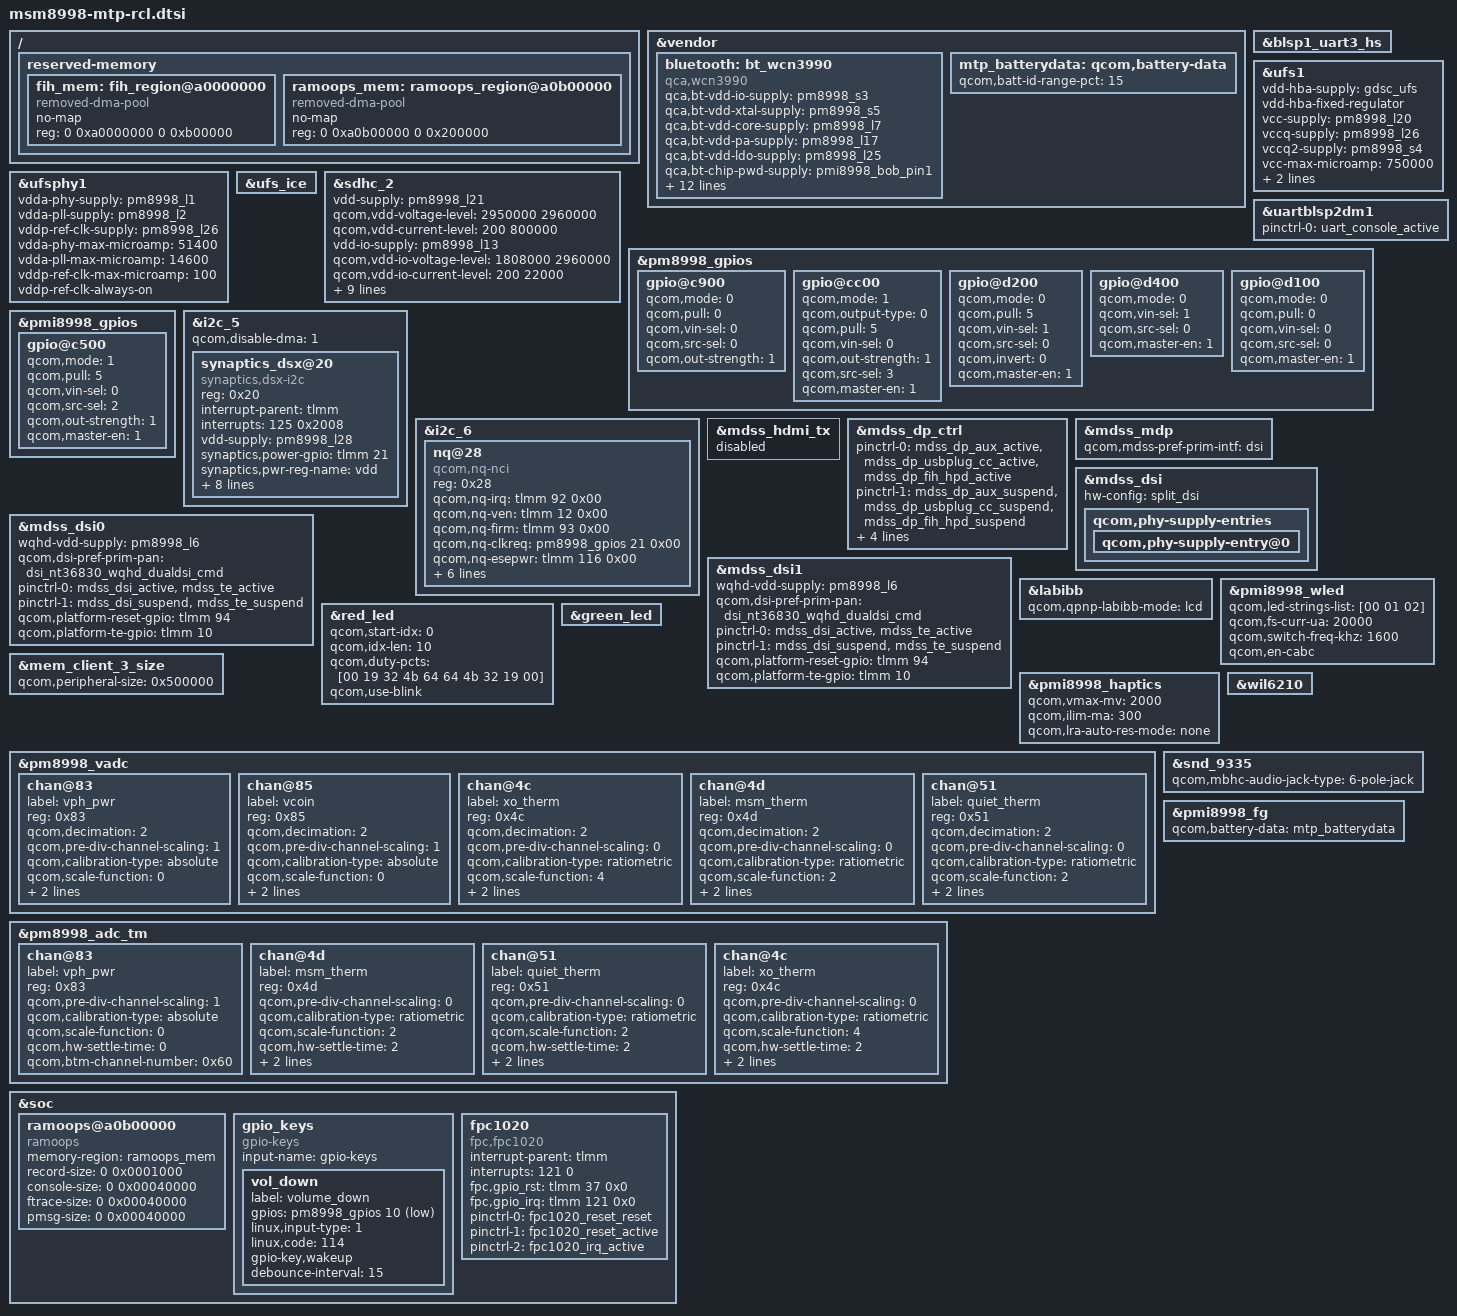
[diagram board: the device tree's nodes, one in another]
/* Copyright (c) 2016-2018, The Linux Foundation. All rights reserved.
 *
 * This program is free software; you can redistribute it and/or modify
 * it under the terms of the GNU General Public License version 2 and
 * only version 2 as published by the Free Software Foundation.
 *
 * This program is distributed in the hope that it will be useful,
 * but WITHOUT ANY WARRANTY; without even the implied warranty of
 * MERCHANTABILITY or FITNESS FOR A PARTICULAR PURPOSE.  See the
 * GNU General Public License for more details.
 */

#include <dt-bindings/interrupt-controller/irq.h>
#include "msm-pm8998-rcl.dtsi"
#include "msm-pmi8998-rcl.dtsi"
#include "msm8998-camera-sensor-mtp-rcl.dtsi"
#include "msm8998-pinctrl-rcl.dtsi"
#include "msm8998-regulator-rcl.dtsi"

/ {
	reserved-memory {
		fih_mem: fih_region@a0000000 { /* for FIH feature */
			compatible = "removed-dma-pool";
			no-map;
			reg = <0 0xa0000000 0 0xb00000>;
		};

		ramoops_mem: ramoops_region@a0b00000 { /* for ramoops feature */
			compatible = "removed-dma-pool";
			no-map;
			reg = <0 0xa0b00000 0 0x200000>;
		};
	};
};

&vendor {
	bluetooth: bt_wcn3990 {
		compatible = "qca,wcn3990";
		qca,bt-vdd-io-supply = <&pm8998_s3>;
		qca,bt-vdd-xtal-supply = <&pm8998_s5>;
		qca,bt-vdd-core-supply = <&pm8998_l7>;
		qca,bt-vdd-pa-supply = <&pm8998_l17>;
		qca,bt-vdd-ldo-supply = <&pm8998_l25>;
		qca,bt-chip-pwd-supply = <&pmi8998_bob_pin1>;
		clocks = <&clock_gcc clk_rf_clk2_pin>;
		clock-names = "rf_clk2";

		qca,bt-vdd-io-voltage-level = <1352000 1352000>;
		qca,bt-vdd-xtal-voltage-level = <2040000 2040000>;
		qca,bt-vdd-core-voltage-level = <1800000 1800000>;
		qca,bt-vdd-pa-voltage-level = <1304000 1304000>;
		qca,bt-vdd-ldo-voltage-level = <3312000 3312000>;
		qca,bt-chip-pwd-voltage-level = <3600000 3600000>;

		qca,bt-vdd-io-current-level = <1>; /* LPM/PFM */
		qca,bt-vdd-xtal-current-level = <1>; /* LPM/PFM */
		qca,bt-vdd-core-current-level = <1>; /* LPM/PFM */
		qca,bt-vdd-pa-current-level = <1>; /* LPM/PFM */
		qca,bt-vdd-ldo-current-level = <1>; /* LPM/PFM */
	};
};

&blsp1_uart3_hs {
	status = "ok";
};

&ufsphy1 {
	vdda-phy-supply = <&pm8998_l1>;
	vdda-pll-supply = <&pm8998_l2>;
	vddp-ref-clk-supply = <&pm8998_l26>;
	vdda-phy-max-microamp = <51400>;
	vdda-pll-max-microamp = <14600>;
	vddp-ref-clk-max-microamp = <100>;
	vddp-ref-clk-always-on;
	status = "ok";
};

&ufs1 {
	vdd-hba-supply = <&gdsc_ufs>;
	vdd-hba-fixed-regulator;
	vcc-supply = <&pm8998_l20>;
	vccq-supply = <&pm8998_l26>;
	vccq2-supply = <&pm8998_s4>;
	vcc-max-microamp = <750000>;
	vccq-max-microamp = <560000>;
	vccq2-max-microamp = <750000>;
	status = "ok";
};

&ufs_ice {
	status = "ok";
};

&sdhc_2 {
	vdd-supply = <&pm8998_l21>;
	qcom,vdd-voltage-level = <2950000 2960000>;
	qcom,vdd-current-level = <200 800000>;

	vdd-io-supply = <&pm8998_l13>;
	qcom,vdd-io-voltage-level = <1808000 2960000>;
	qcom,vdd-io-current-level = <200 22000>;

	pinctrl-names = "active", "sleep";
	pinctrl-0 = <&sdc2_clk_on  &sdc2_cmd_on &sdc2_data_on &sdc2_cd_on>;
	pinctrl-1 = <&sdc2_clk_off &sdc2_cmd_off &sdc2_data_off &sdc2_cd_off>;

	qcom,clk-rates = <400000 20000000 25000000
				50000000 100000000 200000000>;
	qcom,bus-speed-mode = "SDR12", "SDR25", "SDR50", "DDR50", "SDR104";

	cd-gpios = <&tlmm 95 0x1>;

	status = "ok";
};

&uartblsp2dm1 {
	status = "ok";
	pinctrl-names = "default";
	pinctrl-0 = <&uart_console_active>;
};

&pm8998_gpios {
	/* GPIO 10 for Vol- Key */
	gpio@c900 {
		status = "okay";
		qcom,mode = <0>;
		qcom,pull = <0>;
		qcom,vin-sel = <0>;
		qcom,src-sel = <0>;
		qcom,out-strength = <1>;
	};

	gpio@cc00 { /* GPIO 13 */
		qcom,mode = <1>;
		qcom,output-type = <0>;
		qcom,pull = <5>;
		qcom,vin-sel = <0>;
		qcom,out-strength = <1>;
		qcom,src-sel = <3>;
		qcom,master-en = <1>;
		status = "okay";
	};

	gpio@d200 { /* GPIO 19 - wil6210 refclk3_en */
		qcom,mode = <0>;		/* Input */
		qcom,pull = <5>;		/* No Pull */
		qcom,vin-sel = <1>;		/* VIN1 GPIO_MV */
		qcom,src-sel = <0>;		/* GPIO */
		qcom,invert = <0>;		/* Invert */
		qcom,master-en = <1>;		/* Enable GPIO */
		status = "okay";
	};

	/* GPIO 21 (NFC_CLK_REQ) */
	gpio@d400 {
		qcom,mode = <0>;
		qcom,vin-sel = <1>;
		qcom,src-sel = <0>;
		qcom,master-en = <1>;
		status = "okay";
	};

	/* GPIO 18 SMB138X */
	gpio@d100 {
		qcom,mode = <0>;
		qcom,pull = <0>;
		qcom,vin-sel = <0>;
		qcom,src-sel = <0>;
		qcom,master-en = <1>;
		status = "okay";
	};
};

&pmi8998_gpios {
	/* GPIO 6 for the internal QNOVO discharge FET control signal */
	gpio@c500 {
		status = "okay";
		qcom,mode = <1>;
		qcom,pull = <5>;
		qcom,vin-sel = <0>;
		qcom,src-sel = <2>;
		qcom,out-strength = <1>;
		qcom,master-en = <1>;
	};
};

&i2c_5 {
	status = "okay";
	qcom,disable-dma = <1>;

	synaptics_dsx@20 {
		compatible = "synaptics,dsx-i2c";
		reg = <0x20>;
		interrupt-parent = <&tlmm>;
		interrupts = <125 0x2008>;
		vdd-supply = <&pm8998_l28>;
		synaptics,power-gpio = <&tlmm 21 0x00>;
		synaptics,pwr-reg-name = "vdd";
		synaptics,power-on-state = <1>;
		synaptics,display-coords = <0 0 1599 2559>;
		synaptics,panel-coords = <0 0 1599 2703>;
		synaptics,irq-gpio = <&tlmm 125 0x2008>; /* IRQF_ONESHOT | IRQF_TRIGGER_LOW */
		synaptics,reset-gpio = <&tlmm 89 0x00>;
		synaptics,reset-delay-ms = <100>;
		synaptics,reset-on-state = <0>;
		synaptics,reset-active-ms = <20>;
	};
};

&i2c_6 { /* BLSP1 QUP6 (NFC) */
	status = "okay";
	nq@28 {
		compatible = "qcom,nq-nci";
		reg = <0x28>;
		qcom,nq-irq = <&tlmm 92 0x00>;
		qcom,nq-ven = <&tlmm 12 0x00>;
		qcom,nq-firm = <&tlmm 93 0x00>;
		qcom,nq-clkreq = <&pm8998_gpios 21 0x00>;
		qcom,nq-esepwr = <&tlmm 116 0x00>;
		interrupt-parent = <&tlmm>;
		qcom,clk-src = "BBCLK3";
		interrupts = <92 0>;
		interrupt-names = "nfc_irq";
		pinctrl-names = "nfc_active", "nfc_suspend";
		pinctrl-0 = <&nfc_int_active &nfc_enable_active>;
		pinctrl-1 = <&nfc_int_suspend &nfc_enable_suspend>;
		clocks = <&clock_gcc clk_ln_bb_clk3_pin>;
		clock-names = "ref_clk";
	};
};

&mdss_hdmi_tx {
	status = "disabled";
};

&mdss_dp_ctrl {
	pinctrl-names = "mdss_dp_active", "mdss_dp_sleep";
	pinctrl-0 = <&mdss_dp_aux_active &mdss_dp_usbplug_cc_active &mdss_dp_fih_hpd_active>;
	pinctrl-1 = <&mdss_dp_aux_suspend &mdss_dp_usbplug_cc_suspend &mdss_dp_fih_hpd_suspend>;
	qcom,aux-en-gpio = <&tlmm 77 0>;
	qcom,aux-sel-gpio = <&tlmm 78 0>;
	qcom,hpd-gpio = <&tlmm 115 0>;
	qcom,usbplug-cc-gpio = <&tlmm 38 0>;
};

&mdss_mdp {
	qcom,mdss-pref-prim-intf = "dsi";
};

&mdss_dsi {
	hw-config = "split_dsi";

	qcom,phy-supply-entries {
		qcom,phy-supply-entry@0 {
			/delete-property/ qcom,supply-lp-mode-disable-allowed;
		};
	};
};

&mdss_dsi0 {
	wqhd-vdd-supply = <&pm8998_l6>;

	qcom,dsi-pref-prim-pan = <&dsi_nt36830_wqhd_dualdsi_cmd>;
	pinctrl-names = "mdss_default", "mdss_sleep";
	pinctrl-0 = <&mdss_dsi_active &mdss_te_active>;
	pinctrl-1 = <&mdss_dsi_suspend &mdss_te_suspend>;
	qcom,platform-reset-gpio = <&tlmm 94 0>;
	qcom,platform-te-gpio = <&tlmm 10 0>;
};

&mdss_dsi1 {
	wqhd-vdd-supply = <&pm8998_l6>;

	qcom,dsi-pref-prim-pan = <&dsi_nt36830_wqhd_dualdsi_cmd>;
	pinctrl-names = "mdss_default", "mdss_sleep";
	pinctrl-0 = <&mdss_dsi_active &mdss_te_active>;
	pinctrl-1 = <&mdss_dsi_suspend &mdss_te_suspend>;
	qcom,platform-reset-gpio = <&tlmm 94 0>;
	qcom,platform-te-gpio = <&tlmm 10 0>;
};

&labibb {
	status = "ok";
	qcom,qpnp-labibb-mode = "lcd";
};

&pmi8998_wled {
	qcom,led-strings-list = [00 01 02];
	qcom,fs-curr-ua = <20000>;
	qcom,switch-freq-khz = <1600>;
	qcom,en-cabc;
};

&red_led {
	/delete-property/ linux,default-trigger;
	qcom,start-idx = <0>;
	qcom,idx-len = <10>;
	qcom,duty-pcts = [00 19 32 4b 64
			64 4b 32 19 00];
	qcom,use-blink;
};

&green_led {
	/delete-property/ linux,default-trigger;
};

&mem_client_3_size {
	qcom,peripheral-size = <0x500000>;
};

&pmi8998_haptics {
	status = "okay";
	qcom,vmax-mv = <2000>;
	qcom,ilim-ma = <300>;
	qcom,lra-auto-res-mode = "none";
	/delete-property/ qcom,lra-high-z;
	/delete-property/ qcom,lra-res-cal-period;
};

&pm8998_vadc {
	chan@83 {
		label = "vph_pwr";
		reg = <0x83>;
		qcom,decimation = <2>;
		qcom,pre-div-channel-scaling = <1>;
		qcom,calibration-type = "absolute";
		qcom,scale-function = <0>;
		qcom,hw-settle-time = <0>;
		qcom,fast-avg-setup = <0>;
	};

	chan@85 {
		label = "vcoin";
		reg = <0x85>;
		qcom,decimation = <2>;
		qcom,pre-div-channel-scaling = <1>;
		qcom,calibration-type = "absolute";
		qcom,scale-function = <0>;
		qcom,hw-settle-time = <0>;
		qcom,fast-avg-setup = <0>;
	};

	chan@4c {
		label = "xo_therm";
		reg = <0x4c>;
		qcom,decimation = <2>;
		qcom,pre-div-channel-scaling = <0>;
		qcom,calibration-type = "ratiometric";
		qcom,scale-function = <4>;
		qcom,hw-settle-time = <2>;
		qcom,fast-avg-setup = <0>;
	};

	chan@4d {
		label = "msm_therm";
		reg = <0x4d>;
		qcom,decimation = <2>;
		qcom,pre-div-channel-scaling = <0>;
		qcom,calibration-type = "ratiometric";
		qcom,scale-function = <2>;
		qcom,hw-settle-time = <2>;
		qcom,fast-avg-setup = <0>;
	};

	chan@51 {
		label = "quiet_therm";
		reg = <0x51>;
		qcom,decimation = <2>;
		qcom,pre-div-channel-scaling = <0>;
		qcom,calibration-type = "ratiometric";
		qcom,scale-function = <2>;
		qcom,hw-settle-time = <2>;
		qcom,fast-avg-setup = <0>;
	};
};

&pm8998_adc_tm {
	chan@83 {
		label = "vph_pwr";
		reg = <0x83>;
		qcom,pre-div-channel-scaling = <1>;
		qcom,calibration-type = "absolute";
		qcom,scale-function = <0>;
		qcom,hw-settle-time = <0>;
		qcom,btm-channel-number = <0x60>;
	};

	chan@4d {
		label = "msm_therm";
		reg = <0x4d>;
		qcom,pre-div-channel-scaling = <0>;
		qcom,calibration-type = "ratiometric";
		qcom,scale-function = <2>;
		qcom,hw-settle-time = <2>;
		qcom,btm-channel-number = <0x68>;
		qcom,thermal-node;
	};

	chan@51 {
		label = "quiet_therm";
		reg = <0x51>;
		qcom,pre-div-channel-scaling = <0>;
		qcom,calibration-type = "ratiometric";
		qcom,scale-function = <2>;
		qcom,hw-settle-time = <2>;
		qcom,btm-channel-number = <0x70>;
		qcom,thermal-node;
	};

	chan@4c {
		label = "xo_therm";
		reg = <0x4c>;
		qcom,pre-div-channel-scaling = <0>;
		qcom,calibration-type = "ratiometric";
		qcom,scale-function = <4>;
		qcom,hw-settle-time = <2>;
		qcom,btm-channel-number = <0x78>;
		qcom,thermal-node;
	};
};

&wil6210 {
	status = "ok";
};

&snd_9335 {
	qcom,mbhc-audio-jack-type = "6-pole-jack";
};

&soc {
	ramoops@a0b00000 {
		compatible = "ramoops";
		memory-region = <&ramoops_mem>;
		record-size = <0 0x0001000>;
		console-size = <0 0x00040000>;
		ftrace-size = <0 0x00040000>;
		pmsg-size = <0 0x00040000>;
	};

	gpio_keys {
		compatible = "gpio-keys";
		input-name = "gpio-keys";
		status = "okay";

		vol_down {
			label = "volume_down";
			gpios = <&pm8998_gpios 10 0x1>;
			linux,input-type = <1>;
			linux,code = <114>;
			gpio-key,wakeup;
			debounce-interval = <15>;
		};
	};

	fpc1020 {
		compatible = "fpc,fpc1020";
		status = "ok";
		interrupt-parent = <&tlmm>;
		interrupts = <121 0>;
		fpc,gpio_rst = <&tlmm 37 0x0>;
		fpc,gpio_irq = <&tlmm 121 0x0>;

		pinctrl-names = "fpc1020_reset_reset",
				"fpc1020_reset_active",
				"fpc1020_irq_active";

		pinctrl-0 = <&fpc1020_reset_reset>;
		pinctrl-1 = <&fpc1020_reset_active>;
		pinctrl-2 = <&fpc1020_irq_active>;
	};
};

&vendor {
	mtp_batterydata: qcom,battery-data {
		qcom,batt-id-range-pct = <15>;
		#include "../fg-gen3-batterydata-itech-3000mah.dtsi"
		#include "../fg-gen3-batterydata-ascent-3450mah.dtsi"
		#include "../fg-gen3-batterydata-demo-6000mah.dtsi"
	};
};

&pmi8998_fg {
	qcom,battery-data = <&mtp_batterydata>;
};
